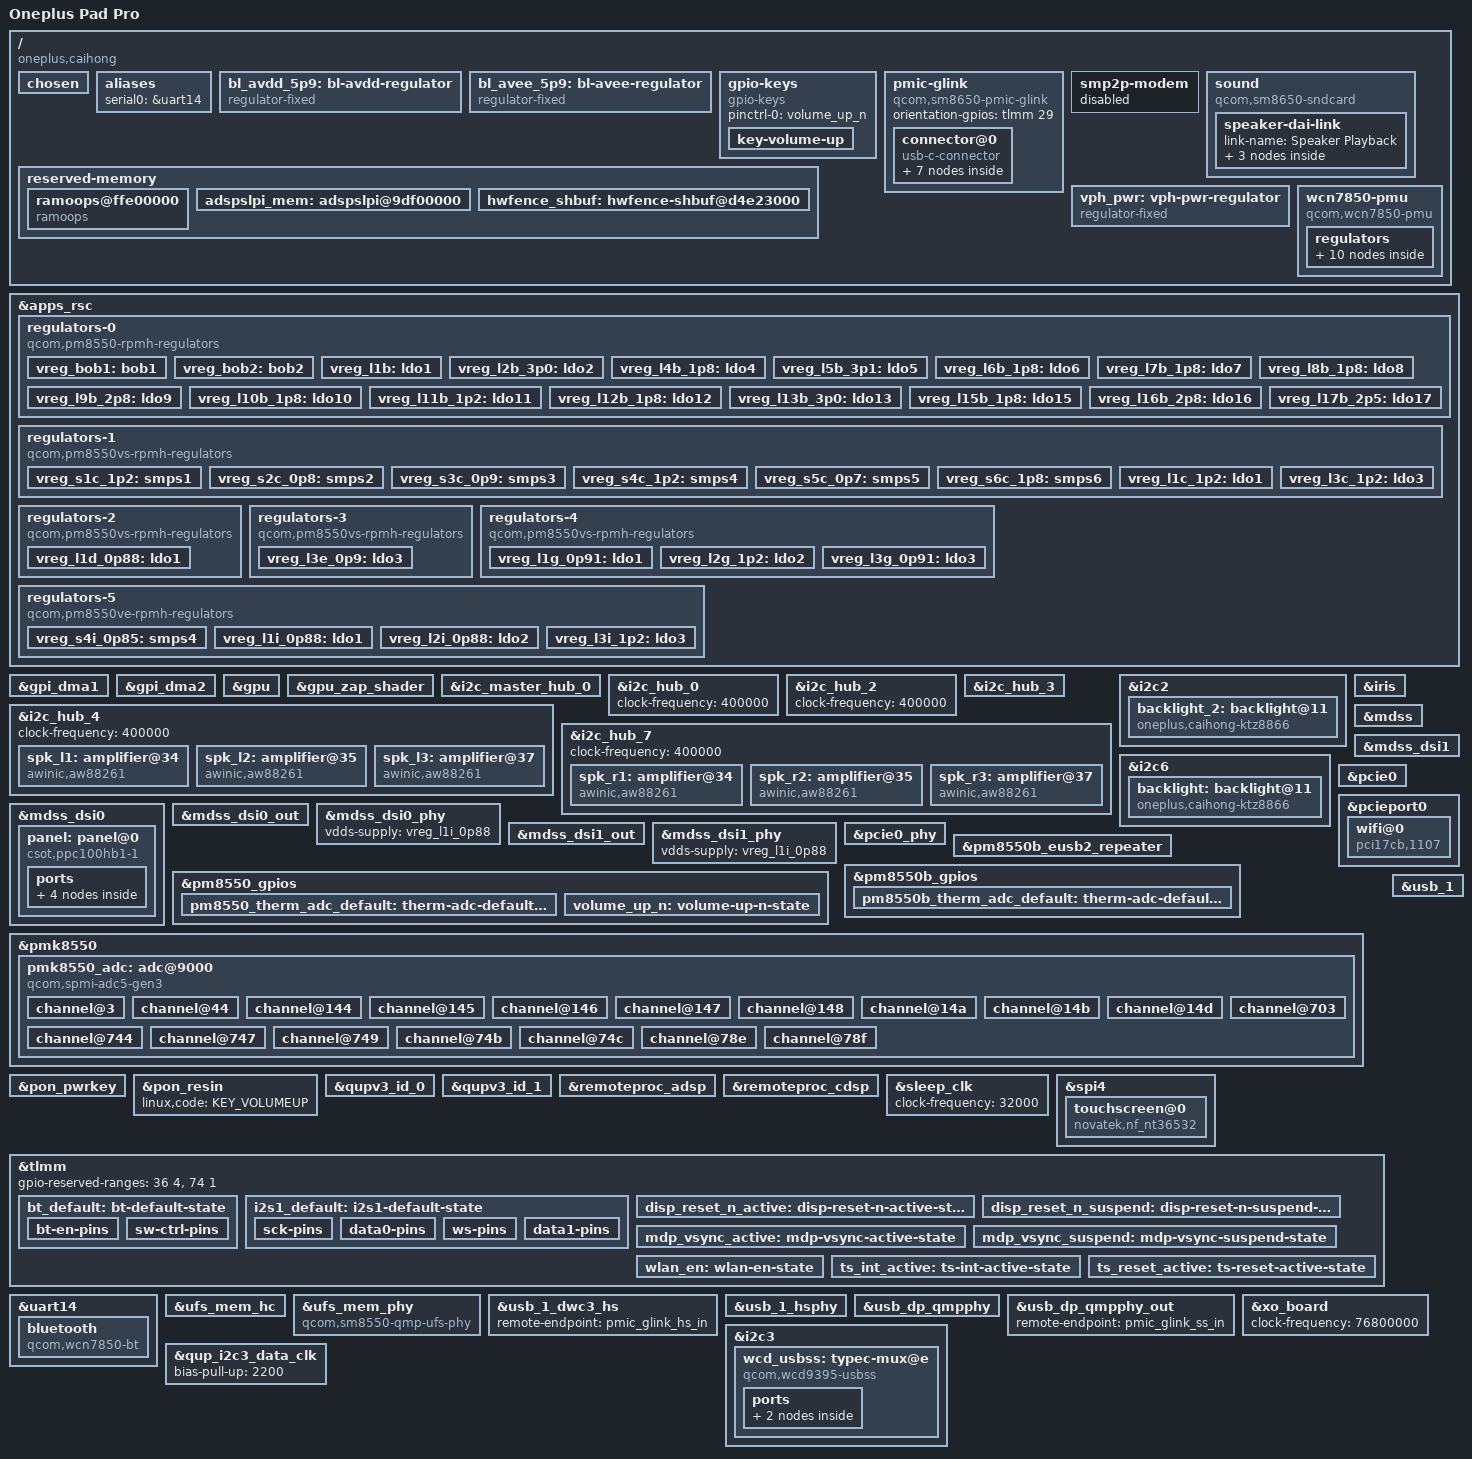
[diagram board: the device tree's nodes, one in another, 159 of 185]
// SPDX-License-Identifier: BSD-3-Clause
/*
 * Based on Qualcomm Reference Device DeviceTree
 *
 * Copyright (c) 2023, Linaro Limited
 * Copyright (c) 2025, Pengyu Luo <mitltlatltl@gmail.com>
 */

/dts-v1/;
#include <dt-bindings/regulator/qcom,rpmh-regulator.h>
#include "sm8650.dtsi"
#include "pm8550.dtsi"
#include "pm8550b.dtsi"
#define PMK8550VE_SID 8
#include "pm8550ve.dtsi"
#include "pm8550vs.dtsi"
#include "pmk8550.dtsi"

/delete-node/ &hwfence_shbuf;

/* No Modem */
/delete-node/ &mpss_mem;
/delete-node/ &q6_mpss_dtb_mem;
/delete-node/ &mpss_dsm_mem;
/delete-node/ &mpss_dsm_mem_2;
/delete-node/ &qlink_logging_mem;
/delete-node/ &remoteproc_mpss;

/* Unused now, and reusable, taking 144 MiB back */
/delete-node/ &trust_ui_vm_mem;
/delete-node/ &oem_vm_mem;
/delete-node/ &qdss_mem;

/ {
	model = "Oneplus Pad Pro";
	compatible = "oneplus,caihong", "qcom,sm8650";
	chassis-type = "tablet";
	chosen {
		#address-cells = <0x02>;
		#size-cells = <0x02>;
		ranges;
		//std-out = "/framebuffer0";
	};
	aliases {
		serial0 = &uart14;
	};

	bl_avdd_5p9: bl-avdd-regulator {
		compatible = "regulator-fixed";
		regulator-name = "bl_avdd_5p9";
		regulator-min-microvolt = <5500000>;
		regulator-max-microvolt = <5500000>;
		regulator-enable-ramp-delay = <233>;
		gpio = <&tlmm 90 GPIO_ACTIVE_HIGH>;
		enable-active-high;
		regulator-boot-on;
	};

	bl_avee_5p9: bl-avee-regulator {
		compatible = "regulator-fixed";
		regulator-name = "bl_avee_5p9";
		regulator-min-microvolt = <5500000>;
		regulator-max-microvolt = <5500000>;
		regulator-enable-ramp-delay = <233>;
		gpio = <&tlmm 91 GPIO_ACTIVE_HIGH>;
		enable-active-high;
		regulator-boot-on;
	};

	gpio-keys {
		compatible = "gpio-keys";

		pinctrl-0 = <&volume_up_n>;
		pinctrl-names = "default";

		key-volume-up {
			label = "Volume Up";
			linux,code = <KEY_VOLUMEDOWN>;
			gpios = <&pm8550_gpios 6 GPIO_ACTIVE_LOW>;
			debounce-interval = <15>;
			linux,can-disable;
			wakeup-source;
		};
	};

	pmic-glink {
		compatible = "qcom,sm8650-pmic-glink",
			     "qcom,sm8550-pmic-glink",
			     "qcom,pmic-glink";
		#address-cells = <1>;
		#size-cells = <0>;
		orientation-gpios = <&tlmm 29 GPIO_ACTIVE_HIGH>;

		connector@0 {
			compatible = "usb-c-connector";
			reg = <0>;

			power-role = "dual";
			data-role = "dual";

			ports {
				#address-cells = <1>;
				#size-cells = <0>;

				port@0 {
					reg = <0>;

					pmic_glink_hs_in: endpoint {
						remote-endpoint = <&usb_1_dwc3_hs>;
					};
				};

				port@1 {
					reg = <1>;

					pmic_glink_ss_in: endpoint {
						remote-endpoint = <&usb_dp_qmpphy_out>;
					};
				};

				port@2 {
					reg = <2>;

					pmic_glink_sbu: endpoint {
						remote-endpoint = <&wcd_usbss_sbu_mux>;
					};
				};

			};
		};
	};

	reserved-memory {
		/*
		 * Keeps the kernel log across a crash or watchdog reset, which
		 * otherwise leaves no trace (no serial console on this tablet).
		 */
		ramoops@ffe00000 {
			compatible = "ramoops";
			reg = <0x0 0xffe00000 0x0 0x200000>;
			record-size = <0x40000>;
			console-size = <0x100000>;
			pmsg-size = <0x40000>;
		};

		adspslpi_mem: adspslpi@9df00000 {
			reg = <0 0x9df00000 0 0x5280000>;
			no-map;
		};

		hwfence_shbuf: hwfence-shbuf@d4e23000 {
			reg = <0 0xd4e23000 0 0x2dd000>;
			no-map;
		};

	};

	/* No Modem */
	smp2p-modem {
		status = "disabled";
	};

	sound {
		compatible = "qcom,sm8650-sndcard", "qcom,sm8450-sndcard";
		model = "OnePlus-Pad2";

		/*
		 * The six AW88261 amplifiers sit on one I2S bus. Mainline
		 * AudioReach has no TDM backend, so they are driven as plain
		 * stereo over SEC_MI2S SD1, each amp picking its side.
		 */
		clocks = <&q6prmcc LPASS_CLK_ID_SEC_MI2S_IBIT LPASS_CLK_ATTRIBUTE_COUPLE_NO>;
		clock-names = "sec-mi2s";

		pinctrl-0 = <&i2s1_default>;
		pinctrl-names = "default";

		speaker-dai-link {
			link-name = "Speaker Playback";

			codec {
				sound-dai = <&spk_l1>, <&spk_l2>, <&spk_l3>,
					    <&spk_r1>, <&spk_r2>, <&spk_r3>;
			};

			cpu {
				sound-dai = <&q6apmbedai SECONDARY_MI2S_RX>;
			};

			platform {
				sound-dai = <&q6apm>;
			};
		};
	};

	vph_pwr: vph-pwr-regulator {
		compatible = "regulator-fixed";

		regulator-name = "vph_pwr";
		regulator-min-microvolt = <3700000>;
		regulator-max-microvolt = <3700000>;

		regulator-always-on;
		regulator-boot-on;
	};

	wcn7850-pmu {
		compatible = "qcom,wcn7850-pmu";

		pinctrl-names = "default";
		pinctrl-0 = <&wlan_en>, <&bt_default>;

		wlan-enable-gpios = <&tlmm 16 GPIO_ACTIVE_HIGH>;
		bt-enable-gpios = <&tlmm 17 GPIO_ACTIVE_HIGH>;

		vdd-supply = <&vreg_s4i_0p85>;
		vddio-supply = <&vreg_l15b_1p8>;
		vddio1p2-supply = <&vreg_l3c_1p2>;
		vddaon-supply = <&vreg_s2c_0p8>;
		vdddig-supply = <&vreg_s3c_0p9>;
		vddrfa1p2-supply = <&vreg_s1c_1p2>;
		vddrfa1p8-supply = <&vreg_s6c_1p8>;

		clocks = <&rpmhcc RPMH_RF_CLK1>;

		regulators {
			vreg_pmu_rfa_cmn: ldo0 {
				regulator-name = "vreg_pmu_rfa_cmn";
			};

			vreg_pmu_aon_0p59: ldo1 {
				regulator-name = "vreg_pmu_aon_0p59";
			};

			vreg_pmu_wlcx_0p8: ldo2 {
				regulator-name = "vreg_pmu_wlcx_0p8";
			};

			vreg_pmu_wlmx_0p85: ldo3 {
				regulator-name = "vreg_pmu_wlmx_0p85";
			};

			vreg_pmu_btcmx_0p85: ldo4 {
				regulator-name = "vreg_pmu_btcmx_0p85";
			};

			vreg_pmu_rfa_0p8: ldo5 {
				regulator-name = "vreg_pmu_rfa_0p8";
			};

			vreg_pmu_rfa_1p2: ldo6 {
				regulator-name = "vreg_pmu_rfa_1p2";
			};

			vreg_pmu_rfa_1p8: ldo7 {
				regulator-name = "vreg_pmu_rfa_1p8";
			};

			vreg_pmu_pcie_0p9: ldo8 {
				regulator-name = "vreg_pmu_pcie_0p9";
			};

			vreg_pmu_pcie_1p8: ldo9 {
				regulator-name = "vreg_pmu_pcie_1p8";
			};
		};
	};
};

&apps_rsc {
	regulators-0 {
		compatible = "qcom,pm8550-rpmh-regulators";

		vdd-bob1-supply = <&vph_pwr>;
		vdd-bob2-supply = <&vph_pwr>;
		vdd-l2-l13-l14-supply = <&vreg_bob1>;
		vdd-l3-supply = <&vreg_s1c_1p2>;
		vdd-l5-l16-supply = <&vreg_bob1>;
		vdd-l6-l7-supply = <&vreg_bob1>;
		vdd-l8-l9-supply = <&vreg_bob1>;
		vdd-l11-supply = <&vreg_s1c_1p2>;
		vdd-l12-supply = <&vreg_s6c_1p8>;
		vdd-l15-supply = <&vreg_s6c_1p8>;
		vdd-l17-supply = <&vreg_bob2>;

		qcom,pmic-id = "b";

		vreg_bob1: bob1 {
			regulator-name = "vreg_bob1";
			regulator-min-microvolt = <3008000>;
			regulator-max-microvolt = <3960000>;
			regulator-initial-mode = <RPMH_REGULATOR_MODE_HPM>;
			regulator-always-on;
		};

		vreg_bob2: bob2 {
			regulator-name = "vreg_bob2";
			regulator-min-microvolt = <2704000>;
			regulator-max-microvolt = <3008000>;
			regulator-initial-mode = <RPMH_REGULATOR_MODE_HPM>;
			regulator-always-on;
		};

		vreg_l1b: ldo1 {
			regulator-name = "vreg_l1b";
			regulator-min-microvolt = <1800000>;
			regulator-max-microvolt = <1800000>;
			regulator-initial-mode = <RPMH_REGULATOR_MODE_HPM>;
			regulator-allow-set-load;
			regulator-allowed-modes = <RPMH_REGULATOR_MODE_LPM
						   RPMH_REGULATOR_MODE_HPM>;
			regulator-always-on;
		};

		vreg_l2b_3p0: ldo2 {
			regulator-name = "vreg_l2b_3p0";
			regulator-min-microvolt = <3008000>;
			regulator-max-microvolt = <3008000>;
			regulator-initial-mode = <RPMH_REGULATOR_MODE_HPM>;
			regulator-allow-set-load;
			regulator-allowed-modes = <RPMH_REGULATOR_MODE_LPM
						   RPMH_REGULATOR_MODE_HPM>;
		};

		vreg_l4b_1p8: ldo4 {
			regulator-name = "vreg_l4b_1p8";
			regulator-min-microvolt = <1800000>;
			regulator-max-microvolt = <1800000>;
			regulator-initial-mode = <RPMH_REGULATOR_MODE_HPM>;
			regulator-allow-set-load;
			regulator-allowed-modes = <RPMH_REGULATOR_MODE_LPM
						   RPMH_REGULATOR_MODE_HPM>;
		};

		vreg_l5b_3p1: ldo5 {
			regulator-name = "vreg_l5b_3p1";
			regulator-min-microvolt = <3104000>;
			regulator-max-microvolt = <3104000>;
			regulator-initial-mode = <RPMH_REGULATOR_MODE_HPM>;
			regulator-allow-set-load;
			regulator-allowed-modes = <RPMH_REGULATOR_MODE_LPM
						   RPMH_REGULATOR_MODE_HPM>;
		};
		vreg_l6b_1p8: ldo6 {
			regulator-name = "vreg_l6b_1p8";
			regulator-min-microvolt = <1800000>;
			regulator-max-microvolt = <3008000>;
			regulator-initial-mode = <RPMH_REGULATOR_MODE_HPM>;
			regulator-allow-set-load;
			regulator-allowed-modes = <RPMH_REGULATOR_MODE_LPM
						   RPMH_REGULATOR_MODE_HPM>;
			regulator-always-on;
		};
		vreg_l7b_1p8: ldo7 {
			regulator-name = "vreg_l7b_1p8";
			regulator-min-microvolt = <1800000>;
			regulator-max-microvolt = <3008000>;
			regulator-initial-mode = <RPMH_REGULATOR_MODE_HPM>;
			regulator-always-on;
		};

		vreg_l8b_1p8: ldo8 {
			regulator-name = "vreg_l8b_1p8";
			regulator-min-microvolt = <1800000>;
			regulator-max-microvolt = <3008000>;
			regulator-initial-mode = <RPMH_REGULATOR_MODE_HPM>;
			regulator-allow-set-load;
			regulatorepss_l3-allowed-modes = <RPMH_REGULATOR_MODE_LPM
						   RPMH_REGULATOR_MODE_HPM>;
			regulator-always-on;
		};
		vreg_l9b_2p8: ldo9 {
			regulator-name = "vreg_l9b_2p8";
			regulator-min-microvolt = <2800000>;
			regulator-max-microvolt = <2800000>;
			regulator-initial-mode = <RPMH_REGULATOR_MODE_HPM>;
			regulator-allow-set-load;
			regulator-allowed-modes = <RPMH_REGULATOR_MODE_LPM
						   RPMH_REGULATOR_MODE_HPM>;
		};

		vreg_l10b_1p8: ldo10 {
			regulator-name = "vreg_l10b_1p8";
			regulator-min-microvolt = <1800000>;
			regulator-max-microvolt = <1800000>;
			regulator-initial-mode = <RPMH_REGULATOR_MODE_HPM>;
			regulator-allow-set-load;
			regulator-allowed-modes = <RPMH_REGULATOR_MODE_LPM
						   RPMH_REGULATOR_MODE_HPM>;
		};
		vreg_l11b_1p2: ldo11 {
			regulator-name = "vreg_l11b_1p2";
			regulator-min-microvolt = <1200000>;
			regulator-max-microvolt = <1200000>;
			regulator-initial-mode = <RPMH_REGULATOR_MODE_HPM>;
			regulator-allow-set-load;
			regulator-allowed-modes = <RPMH_REGULATOR_MODE_LPM
						   RPMH_REGULATOR_MODE_HPM>;
			regulator-always-on;
		};
		vreg_l12b_1p8: ldo12 {
			regulator-name = "vreg_l12b_1p8";
			regulator-min-microvolt = <1800000>;
			regulator-max-microvolt = <1800000>;
			regulator-initial-mode = <RPMH_REGULATOR_MODE_HPM>;
			regulator-allow-set-load;
			regulator-always-on;
			regulator-allowed-modes = <RPMH_REGULATOR_MODE_LPM
						   RPMH_REGULATOR_MODE_HPM>;
		};
		vreg_l13b_3p0: ldo13 {
			regulator-name = "vreg_l13b_3p0";
			regulator-min-microvolt = <3000000>;
			regulator-max-microvolt = <3200000>;
			regulator-initial-mode = <RPMH_REGULATOR_MODE_HPM>;
			regulator-allow-set-load;
			regulator-allowed-modes = <RPMH_REGULATOR_MODE_LPM
						   RPMH_REGULATOR_MODE_HPM>;
			regulator-always-on;
		};
		vreg_l15b_1p8: ldo15 {
			regulator-name = "vreg_l15b_1p8";
			regulator-min-microvolt = <1800000>;
			regulator-max-microvolt = <1800000>;
			regulator-initial-mode = <RPMH_REGULATOR_MODE_HPM>;
			regulator-allow-set-load;
			regulator-allowed-modes = <RPMH_REGULATOR_MODE_LPM
						   RPMH_REGULATOR_MODE_HPM>;
		};

		vreg_l16b_2p8: ldo16 {
			regulator-name = "vreg_l16b_2p8";
			regulator-min-microvolt = <2800000>;
			regulator-max-microvolt = <2800000>;
			regulator-initial-mode = <RPMH_REGULATOR_MODE_HPM>;
			regulator-allow-set-load;
			regulator-allowed-modes = <RPMH_REGULATOR_MODE_LPM
						   RPMH_REGULATOR_MODE_HPM>;
		};

		vreg_l17b_2p5: ldo17 {
			regulator-name = "vreg_l17b_2p5";
			regulator-min-microvolt = <2504000>;
			regulator-max-microvolt = <2504000>;
			regulator-initial-mode = <RPMH_REGULATOR_MODE_HPM>;
			regulator-allow-set-load;
			regulator-allowed-modes = <RPMH_REGULATOR_MODE_LPM
						   RPMH_REGULATOR_MODE_HPM>;
		};
	};

	regulators-1 {
		compatible = "qcom,pm8550vs-rpmh-regulators";

		vdd-l1-supply = <&vreg_s1c_1p2>;
		vdd-l2-supply = <&vreg_s1c_1p2>;
		vdd-l3-supply = <&vreg_s1c_1p2>;
		vdd-s1-supply = <&vph_pwr>;
		vdd-s2-supply = <&vph_pwr>;
		vdd-s3-supply = <&vph_pwr>;
		vdd-s4-supply = <&vph_pwr>;
		vdd-s5-supply = <&vph_pwr>;
		vdd-s6-supply = <&vph_pwr>;

		qcom,pmic-id = "c";

		vreg_s1c_1p2: smps1 {
			regulator-name = "vreg_s1c_1p2";
			regulator-min-microvolt = <1316000>;
			regulator-max-microvolt = <1316000>;
			regulator-initial-mode = <RPMH_REGULATOR_MODE_HPM>;
		};

		vreg_s2c_0p8: smps2 {
			regulator-name = "vreg_s2c_0p8";
			regulator-min-microvolt = <976000>;
			regulator-max-microvolt = <976000>;
			regulator-initial-mode = <RPMH_REGULATOR_MODE_HPM>;
		};

		vreg_s3c_0p9: smps3 {
			regulator-name = "vreg_s3c_0p9";
			regulator-min-microvolt = <916000>;
			regulator-max-microvolt = <916000>;
			regulator-initial-mode = <RPMH_REGULATOR_MODE_HPM>;
		};

		vreg_s4c_1p2: smps4 {
			regulator-name = "vreg_s4c_1p2";
			regulator-min-microvolt = <1200000>;
			regulator-max-microvolt = <1280000>;
			regulator-initial-mode = <RPMH_REGULATOR_MODE_HPM>;
		};

		vreg_s5c_0p7: smps5 {
			regulator-name = "vreg_s5c_0p7";
			regulator-min-microvolt = <300000>;
			regulator-max-microvolt = <900000>;
			regulator-initial-mode = <RPMH_REGULATOR_MODE_HPM>;
		};

		vreg_s6c_1p8: smps6 {
			regulator-name = "vreg_s6c_1p8";
			regulator-min-microvolt = <1864000>;
			regulator-max-microvolt = <1864000>;
			regulator-initial-mode = <RPMH_REGULATOR_MODE_HPM>;
		};

		vreg_l1c_1p2: ldo1 {
			regulator-name = "vreg_l1c_1p2";
			regulator-min-microvolt = <1100000>;
			regulator-max-microvolt = <1200000>;
			regulator-initial-mode = <RPMH_REGULATOR_MODE_HPM>;
			regulator-allow-set-load;
			regulator-allowed-modes = <RPMH_REGULATOR_MODE_LPM
						   RPMH_REGULATOR_MODE_HPM>;
		};

		vreg_l3c_1p2: ldo3 {
			regulator-name = "vreg_l3c_1p2";
			regulator-min-microvolt = <1200000>;
			regulator-max-microvolt = <1200000>;
			regulator-initial-mode = <RPMH_REGULATOR_MODE_HPM>;
			regulator-allow-set-load;
			regulator-allowed-modes = <RPMH_REGULATOR_MODE_LPM
						   RPMH_REGULATOR_MODE_HPM>;
		};
	};

	regulators-2 {
		compatible = "qcom,pm8550vs-rpmh-regulators";

		vdd-l1-supply = <&vreg_s3c_0p9>;

		qcom,pmic-id = "d";

		vreg_l1d_0p88: ldo1 {
			regulator-name = "vreg_l1d_0p88";
			regulator-min-microvolt = <880000>;
			regulator-max-microvolt = <920000>;
			regulator-initial-mode = <RPMH_REGULATOR_MODE_HPM>;
			regulator-allow-set-load;
			regulator-allowed-modes = <RPMH_REGULATOR_MODE_LPM
						   RPMH_REGULATOR_MODE_HPM>;
		};
	};

	regulators-3 {
		compatible = "qcom,pm8550vs-rpmh-regulators";

		vdd-l3-supply = <&vreg_s3c_0p9>;

		qcom,pmic-id = "e";

		vreg_l3e_0p9: ldo3 {
			regulator-name = "vreg_l3e_0p9";
			regulator-min-microvolt = <880000>;
			regulator-max-microvolt = <920000>;
			regulator-initial-mode = <RPMH_REGULATOR_MODE_HPM>;
			regulator-allow-set-load;
			regulator-allowed-modes = <RPMH_REGULATOR_MODE_LPM
						   RPMH_REGULATOR_MODE_HPM>;
		};
	};

	regulators-4 {
		compatible = "qcom,pm8550vs-rpmh-regulators";

		vdd-l1-supply = <&vreg_s3c_0p9>;
		vdd-l3-supply = <&vreg_s3c_0p9>;

		qcom,pmic-id = "g";

		vreg_l1g_0p91: ldo1 {
			regulator-name = "vreg_l1g_0p91";
			regulator-min-microvolt = <912000>;
			regulator-max-microvolt = <920000>;
			regulator-initial-mode = <RPMH_REGULATOR_MODE_HPM>;
			regulator-allow-set-load;
			regulator-allowed-modes = <RPMH_REGULATOR_MODE_LPM
						   RPMH_REGULATOR_MODE_HPM>;
		};

		vreg_l2g_1p2: ldo2 {
			regulator-name = "vreg_l2g_1p2";
			regulator-min-microvolt = <1200000>;
			regulator-max-microvolt = <1200000>;
			regulator-initial-mode = <RPMH_REGULATOR_MODE_HPM>;
			regulator-allow-set-load;
			regulator-allowed-modes = <RPMH_REGULATOR_MODE_LPM
						   RPMH_REGULATOR_MODE_HPM>;
		};

		vreg_l3g_0p91: ldo3 {
			regulator-name = "vreg_l3g_0p91";
			regulator-min-microvolt = <880000>;
			regulator-max-microvolt = <912000>;
			regulator-initial-mode = <RPMH_REGULATOR_MODE_HPM>;
			regulator-allow-set-load;
			regulator-allowed-modes = <RPMH_REGULATOR_MODE_LPM
						   RPMH_REGULATOR_MODE_HPM>;
		};
	};

	regulators-5 {
		compatible = "qcom,pm8550ve-rpmh-regulators";

		vdd-l1-supply = <&vreg_s3c_0p9>;
		vdd-l2-supply = <&vreg_s3c_0p9>;
		vdd-l3-supply = <&vreg_s1c_1p2>;
		vdd-s4-supply = <&vph_pwr>;

		qcom,pmic-id = "i";

		vreg_s4i_0p85: smps4 {
			regulator-name = "vreg_s4i_0p85";
			regulator-min-microvolt = <940000>;
			regulator-max-microvolt = <940000>;
			regulator-initial-mode = <RPMH_REGULATOR_MODE_HPM>;
		};

		vreg_l1i_0p88: ldo1 {
			regulator-name = "vreg_l1i_0p88";
			regulator-min-microvolt = <880000>;
			regulator-max-microvolt = <912000>;
			regulator-initial-mode = <RPMH_REGULATOR_MODE_HPM>;
			regulator-allow-set-load;
			regulator-allowed-modes = <RPMH_REGULATOR_MODE_LPM
						   RPMH_REGULATOR_MODE_HPM>;
		};

		vreg_l2i_0p88: ldo2 {
			regulator-name = "vreg_l2i_0p88";
			regulator-min-microvolt = <880000>;
			regulator-max-microvolt = <912000>;
			regulator-initial-mode = <RPMH_REGULATOR_MODE_HPM>;
			regulator-allow-set-load;
			regulator-allowed-modes = <RPMH_REGULATOR_MODE_LPM
						   RPMH_REGULATOR_MODE_HPM>;
		};

		vreg_l3i_1p2: ldo3 {
			regulator-name = "vreg_l3i_0p91";
			regulator-min-microvolt = <1200000>;
			regulator-max-microvolt = <1200000>;
			regulator-initial-mode = <RPMH_REGULATOR_MODE_HPM>;
			regulator-allow-set-load;
			regulator-allowed-modes = <RPMH_REGULATOR_MODE_LPM
						   RPMH_REGULATOR_MODE_HPM>;
		};
	};
};

&gpi_dma1 {
	status = "okay";
};

&gpi_dma2 {
	status = "okay";
};

&gpu {
	status = "okay";
};

&gpu_zap_shader {
	firmware-name = "qcom/sm8650/Oneplus/caihong/gen70900_zap.mbn";
};

&i2c_master_hub_0 {
	status = "okay";
};

&i2c_hub_0 {
	clock-frequency = <400000>;

	status = "okay";

	/* sc8547-charger-secondary@6F */
};

&i2c_hub_2 {
	clock-frequency = <400000>;

	status = "okay";

	/* sc8547-charger-primary@6F */
};

&i2c_hub_3 {
	status = "okay";

	/* pencil-wireless-charger-cps8601@41 */
};

&i2c_hub_4 {
	clock-frequency = <400000>;

	status = "okay";

	/* left speakers */
	spk_l1: amplifier@34 {
		compatible = "awinic,aw88261";
		reg = <0x34>;
		#sound-dai-cells = <0>;
		dvdd-supply = <&vreg_l15b_1p8>;
		firmware-name = "aw882xx_acf.bin";
		awinic,audio-channel = <0>;
		awinic,i2s-chsel = <1>;
		awinic,sync-flag;
		sound-name-prefix = "SpkL1";
	};

	spk_l2: amplifier@35 {
		compatible = "awinic,aw88261";
		reg = <0x35>;
		#sound-dai-cells = <0>;
		dvdd-supply = <&vreg_l15b_1p8>;
		firmware-name = "aw882xx_acf.bin";
		awinic,audio-channel = <2>;
		awinic,i2s-chsel = <1>;
		awinic,sync-flag;
		sound-name-prefix = "SpkL2";
	};

	spk_l3: amplifier@37 {
		compatible = "awinic,aw88261";
		reg = <0x37>;
		#sound-dai-cells = <0>;
		dvdd-supply = <&vreg_l15b_1p8>;
		firmware-name = "aw882xx_acf.bin";
		awinic,audio-channel = <6>;
		awinic,i2s-chsel = <1>;
		awinic,sync-flag;
		sound-name-prefix = "SpkL3";
	};
};

&i2c_hub_7 {
	clock-frequency = <400000>;

	status = "okay";

	/* right speakers */
	spk_r1: amplifier@34 {
		compatible = "awinic,aw88261";
		reg = <0x34>;
		#sound-dai-cells = <0>;
		dvdd-supply = <&vreg_l15b_1p8>;
		firmware-name = "aw882xx_acf.bin";
		awinic,audio-channel = <1>;
		awinic,i2s-chsel = <2>;
		awinic,sync-flag;
		sound-name-prefix = "SpkR1";
	};

	spk_r2: amplifier@35 {
		compatible = "awinic,aw88261";
		reg = <0x35>;
		#sound-dai-cells = <0>;
		dvdd-supply = <&vreg_l15b_1p8>;
		firmware-name = "aw882xx_acf.bin";
		awinic,audio-channel = <3>;
		awinic,i2s-chsel = <2>;
		awinic,sync-flag;
		sound-name-prefix = "SpkR2";
	};

	spk_r3: amplifier@37 {
		compatible = "awinic,aw88261";
		reg = <0x37>;
		#sound-dai-cells = <0>;
		dvdd-supply = <&vreg_l15b_1p8>;
		firmware-name = "aw882xx_acf.bin";
		awinic,audio-channel = <5>;
		awinic,i2s-chsel = <2>;
		awinic,sync-flag;
		sound-name-prefix = "SpkR3";
	};
};

&i2c2 {
	status = "okay";

	/* secondary kinetic,ktz8866@11 */

	backlight_2: backlight@11 {
		compatible = "oneplus,caihong-ktz8866", "kinetic,ktz8866";
		reg = <0x11>;
		/* HW enable shared with the primary KTZ8866 */
		enable-gpios = <&tlmm 89 GPIO_ACTIVE_HIGH>;
		vddpos-supply = <&bl_avdd_5p9>;
		vddneg-supply = <&bl_avee_5p9>;
		current-num-sinks = <5>;
		kinetic,current-ramp-delay-ms = <128>;
		kinetic,led-enable-ramp-delay-ms = <1>;
		kinetic,enable-lcd-bias;
		default-brightness = <100>;
	};

};

&i2c6 {
	status = "okay";

	backlight: backlight@11 {
		compatible = "oneplus,caihong-ktz8866", "kinetic,ktz8866";
		reg = <0x11>;
		enable-gpios = <&tlmm 89 GPIO_ACTIVE_HIGH>;
		vddpos-supply = <&bl_avdd_5p9>;
		vddneg-supply = <&bl_avee_5p9>;
		current-num-sinks = <5>;
		kinetic,current-ramp-delay-ms = <128>;
		kinetic,led-enable-ramp-delay-ms = <1>;
		kinetic,enable-lcd-bias;
		default-brightness = <100>;
	};

};

&iris {
	firmware-name = "qcom/sm8650/Oneplus/caihong/vpu33_4v.mbn";

	status = "okay";
};

&mdss {
	status = "okay";
};

&mdss_dsi0 {
	vdda-supply = <&vreg_l3i_1p2>;

	qcom,dual-dsi-mode;
	qcom,dual-panel;
	qcom,master-dsi;
	qcom,sync-dual-dsi;

	status = "okay";

	panel: panel@0 {
		status = "okay";
		compatible = "csot,ppc100hb1-1","novatek,nt36532";
		reg = <0>;

		reset-gpios = <&tlmm 133 GPIO_ACTIVE_LOW>;

		vddio-supply = <&vreg_l12b_1p8>;
		vci-supply = <&vreg_l13b_3p0>;
		vdd-supply = <&vreg_l11b_1p2>;
		backlight = <&backlight>;
		pinctrl-0 = <&disp_reset_n_active>, <&mdp_vsync_active>;
		pinctrl-1 = <&disp_reset_n_suspend>, <&mdp_vsync_suspend>;
		pinctrl-names = "default", "sleep";

		ports {
			#address-cells = <1>;
			#size-cells = <0>;

			port@0 {
				reg = <0>;

				panel_in_0: endpoint {
					remote-endpoint = <&mdss_dsi0_out>;
				};
			};

			port@1 {
				reg = <1>;

				panel_in_1: endpoint {
					remote-endpoint = <&mdss_dsi1_out>;
				};
			};
		};
	};
};

&mdss_dsi0_out {
	status = "okay";
	remote-endpoint = <&panel_in_0>;
	data-lanes = <0 1 2 3>;
};

&mdss_dsi0_phy {
	vdds-supply = <&vreg_l1i_0p88>;
	status = "okay";
};

&mdss_dsi1 {
	vdda-supply = <&vreg_l3i_1p2>;

	qcom,dual-dsi-mode;
	qcom,dual-panel;
	qcom,sync-dual-dsi;
	qcom,slave-dsi;
	status = "okay";

	assigned-clock-parents = <&mdss_dsi0_phy DSI_BYTE_PLL_CLK>,
				 <&mdss_dsi0_phy DSI_PIXEL_PLL_CLK>;
};

&mdss_dsi1_out {
	status = "okay";
	remote-endpoint = <&panel_in_1>;
	data-lanes = <0 1 2 3>;
};

&mdss_dsi1_phy {
	vdds-supply = <&vreg_l1i_0p88>;
	status = "okay";
};

/*
 * DisplayPort over USB-C kept disabled for now; not needed for the DSI
 * panel.
&mdss_dp0 {
	status = "okay";
};

&mdss_dp0_out {
	status = "okay";
	data-lanes = <0 1>;
};
*/

&pcie0 {
	/*
	 * MSIs written by the endpoint never reach the GIC ITS on this board
	 * (the root port's own MSIs do), so use the controller's internal
	 * MSI instead.
	 */
	/delete-property/ msi-map;
	/delete-property/ msi-map-mask;

	wake-gpios = <&tlmm 96 GPIO_ACTIVE_HIGH>;
	perst-gpios = <&tlmm 94 GPIO_ACTIVE_LOW>;

	pinctrl-0 = <&pcie0_default_state>;
	pinctrl-names = "default";

	status = "okay";
};

&pcieport0 {
	wifi@0 {
		compatible = "pci17cb,1107";
		reg = <0x10000 0x0 0x0 0x0 0x0>;

		vddrfacmn-supply = <&vreg_pmu_rfa_cmn>;
		vddaon-supply = <&vreg_pmu_aon_0p59>;
		vddwlcx-supply = <&vreg_pmu_wlcx_0p8>;
		vddwlmx-supply = <&vreg_pmu_wlmx_0p85>;
		vddrfa0p8-supply = <&vreg_pmu_rfa_0p8>;
		vddrfa1p2-supply = <&vreg_pmu_rfa_1p2>;
		vddrfa1p8-supply = <&vreg_pmu_rfa_1p8>;
		vddpcie0p9-supply = <&vreg_pmu_pcie_0p9>;
		vddpcie1p8-supply = <&vreg_pmu_pcie_1p8>;
	};
};

&pcie0_phy {
	vdda-phy-supply = <&vreg_l1i_0p88>;
	vdda-pll-supply = <&vreg_l3i_1p2>;

	status = "okay";
};

&pm8550_gpios {
	/* Thermistors read through the ADC: battery connector, SuperVOOC MOS */
	pm8550_therm_adc_default: therm-adc-default-state {
		pins = "gpio4", "gpio12";
		function = "normal";
		bias-high-impedance;
		bias-disable;
	};

	volume_up_n: volume-up-n-state {
		pins = "gpio6";
		function = "normal";
		bias-pull-up;
		input-enable;
		power-source = <1>;
	};
};

&pm8550b_eusb2_repeater {
	vdd18-supply = <&vreg_l15b_1p8>;
	vdd3-supply = <&vreg_l5b_3p1>;
};

&pm8550b_gpios {
	/*
	 * Thermistors read through the ADC: USB port left/right and sub-board.
	 * Left in their reset state (input, 10 uA pull-down) they read ~60 C.
	 */
	pm8550b_therm_adc_default: therm-adc-default-state {
		pins = "gpio5", "gpio6", "gpio10";
		function = "normal";
		bias-high-impedance;
		bias-disable;
	};
};

&pmk8550 {
	pmk8550_adc: adc@9000 {
		compatible = "qcom,spmi-adc5-gen3";
		reg = <0x9000>, <0x9100>;
		interrupts = <0x0 0x90 0x1 IRQ_TYPE_EDGE_RISING>,
			     <0x0 0x91 0x1 IRQ_TYPE_EDGE_RISING>;
		#address-cells = <1>;
		#size-cells = <0>;
		#io-channel-cells = <1>;
		#thermal-sensor-cells = <1>;

		pinctrl-0 = <&pm8550_therm_adc_default>, <&pm8550b_therm_adc_default>;
		pinctrl-names = "default";

		channel@3 {
			reg = <0x3>;
			label = "pmk8550_die_temp";
			qcom,pre-scaling = <1 1>;
		};

		channel@44 {
			reg = <0x44>;
			label = "pmk8550_xo_therm";
			qcom,pre-scaling = <1 1>;
			qcom,ratiometric;
			qcom,hw-settle-time = <200>;
		};

		channel@144 {
			reg = <0x144>;
			label = "pm8550_msm_therm";
			qcom,pre-scaling = <1 1>;
			qcom,ratiometric;
			qcom,hw-settle-time = <200>;
		};

		channel@145 {
			reg = <0x145>;
			label = "pm8550_cam_flash_therm";
			qcom,pre-scaling = <1 1>;
			qcom,ratiometric;
			qcom,hw-settle-time = <200>;
		};

		channel@146 {
			reg = <0x146>;
			label = "pm8550_wlan_therm";
			qcom,pre-scaling = <1 1>;
			qcom,ratiometric;
			qcom,hw-settle-time = <200>;
		};

		channel@147 {
			reg = <0x147>;
			label = "pm8550_pa_therm_1";
			qcom,pre-scaling = <1 1>;
			qcom,ratiometric;
			qcom,hw-settle-time = <200>;
		};

		channel@148 {
			reg = <0x148>;
			label = "pm8550_rear_tof_therm";
			qcom,pre-scaling = <1 1>;
			qcom,ratiometric;
			qcom,hw-settle-time = <200>;
		};

		channel@14a {
			reg = <0x14a>;
			label = "pm8550_pa_therm_2";
			qcom,pre-scaling = <1 1>;
			qcom,ratiometric;
			qcom,hw-settle-time = <200>;
		};

		channel@14b {
			reg = <0x14b>;
			label = "batt_con_therm";
			qcom,pre-scaling = <1 1>;
			qcom,ratiometric;
			qcom,hw-settle-time = <200>;
		};

		channel@14d {
			reg = <0x14d>;
			label = "svooc_mos_btb_therm";
			qcom,pre-scaling = <1 1>;
			qcom,ratiometric;
			qcom,hw-settle-time = <200>;
		};

		channel@703 {
			reg = <0x703>;
			label = "pm8550b_die_temp";
			qcom,pre-scaling = <1 1>;
		};

		channel@744 {
			reg = <0x744>;
			label = "pm8550b_batt_therm";
			qcom,pre-scaling = <1 1>;
			qcom,ratiometric;
			qcom,hw-settle-time = <200>;
		};

		channel@747 {
			reg = <0x747>;
			label = "usb_con_therm";
			qcom,pre-scaling = <1 1>;
			qcom,ratiometric;
			qcom,hw-settle-time = <200>;
		};

		channel@749 {
			reg = <0x749>;
			label = "usb_temp_r";
			qcom,pre-scaling = <1 1>;
			qcom,ratiometric;
			qcom,hw-settle-time = <200>;
		};

		channel@74b {
			reg = <0x74b>;
			label = "usb_temp_l";
			qcom,pre-scaling = <1 1>;
			qcom,ratiometric;
			qcom,hw-settle-time = <200>;
		};

		channel@74c {
			reg = <0x74c>;
			label = "subboard_therm";
			qcom,pre-scaling = <1 1>;
			qcom,ratiometric;
			qcom,hw-settle-time = <200>;
		};

		channel@78e {
			reg = <0x78e>;
			label = "pm8550b_vph_pwr";
			qcom,pre-scaling = <1 3>;
		};

		channel@78f {
			reg = <0x78f>;
			label = "pm8550b_vbat_sns_qbg";
			qcom,pre-scaling = <1 3>;
		};
	};
};

&pon_pwrkey {
	status = "okay";
};

&pon_resin {
	linux,code = <KEY_VOLUMEUP>;

	status = "okay";
};

&qupv3_id_0 {
	status = "okay";
};

&qupv3_id_1 {
	status = "okay";
};

&remoteproc_adsp {
	firmware-name = "qcom/sm8650/Oneplus/caihong/adsp.mbn",
			"qcom/sm8650/Oneplus/caihong/adsp_dtb.mbn";

	status = "okay";
};

&remoteproc_cdsp {
	firmware-name = "qcom/sm8650/Oneplus/caihong/cdsp.mbn",
			"qcom/sm8650/Oneplus/caihong/cdsp_dtb.mbn";

	status = "okay";
};

&sleep_clk {
	clock-frequency = <32000>;
};

&spi4 {
	status = "okay";

	/*
	 * Novatek NT36532 in-cell touch, driven by the out-of-tree Oplus
	 * "no-flash" driver. It has no flash, so its firmware is downloaded on
	 * every power-up from firmware-data-0, which the board packaging adds
	 * to the DTB (the firmware is not redistributable).
	 */
	touchscreen@0 {
		compatible = "novatek,nf_nt36532";
		reg = <0>;
		spi-max-frequency = <12000000>;

		interrupts-extended = <&tlmm 162 IRQ_TYPE_EDGE_FALLING>;
		irq-gpio = <&tlmm 162 0x2002>;
		reset-gpio = <&tlmm 161 GPIO_ACTIVE_HIGH>;
		cs-gpio = <&tlmm 51 GPIO_ACTIVE_HIGH>;

		pinctrl-0 = <&ts_int_active>, <&ts_reset_active>;
		pinctrl-names = "default";

		panel = <&panel>;

		project_id = <23926>;
		firmware_name = "0X21N2NI9N19";
		platform_support_project = <23926 23927 23976 23978>;
		platform_support_project_dir = <23926 23926 23926 23926>;
		platform_support_project_commandline =
			"mdss_dsi_panel_csot_nt36532_2120_3000_dual_dsc_144hz_vid";

		touchpanel,max-num-support = <10>;
		touchpanel,tx-rx-num = <60 40>;
		touchpanel,panel-coords = <21200 30000>;
		touchpanel,display-coords = <2120 3000>;
		touchpanel,touchmajor-limit = <0 60>;
		touchpanel,irq_need_dev_resume_time = <500>;
		touchpanel,int-mode = <1>;
		touchpanel,button-type = <4>;
		tp_type = <15>;
		panel_type = <15>;

		incell_screen;
		fw_edge_limit_support;
		black_gesture_support;
		charger_pump_support;
		esd_handle_support;
		black_gesture_test_support;
		game_switch_support;
		noflash_support;
		lcd_trigger_load_tp_fw_support;
		smart_gesture_support;
		pressure_report_support;
		pen_support;
		waterproof_support;
		irq_need_dev_resume_ok;
		fw_update_app_support;
		health_monitor_support;
		fw_update_in_probe_with_headfile;
		black_gesture_indep_support;
		report_rate_limit;
	};
};

&tlmm {
	gpio-reserved-ranges = <36 4>, <74 1>;

	bt_default: bt-default-state {
		bt-en-pins {
			pins = "gpio17";
			function = "gpio";
			drive-strength = <16>;
			bias-disable;
		};

		sw-ctrl-pins {
			pins = "gpio18";
			function = "gpio";
			bias-pull-down;
		};
	};
	i2s1_default: i2s1-default-state {
		sck-pins {
			pins = "gpio121";
			function = "i2s1_sck";
			drive-strength = <6>;
			bias-disable;
		};

		data0-pins {
			pins = "gpio122";
			function = "i2s1_data0";
			drive-strength = <6>;
			bias-disable;
		};

		ws-pins {
			pins = "gpio123";
			function = "i2s1_ws";
			drive-strength = <6>;
			bias-disable;
		};

		data1-pins {
			pins = "gpio124";
			function = "i2s1_data1";
			drive-strength = <6>;
			bias-disable;
		};
	};

	disp_reset_n_active: disp-reset-n-active-state {
		pins = "gpio133";
		function = "gpio";
		drive-strength = <8>;
		bias-disable;
	};

	disp_reset_n_suspend: disp-reset-n-suspend-state {
		pins = "gpio133";
		function = "gpio";
		drive-strength = <2>;
		bias-pull-down;
	};

	mdp_vsync_active: mdp-vsync-active-state {
		pins = "gpio86";
		function = "mdp_vsync";
		drive-strength = <2>;
		bias-pull-down;
	};

	mdp_vsync_suspend: mdp-vsync-suspend-state {
		pins = "gpio86";
		function = "mdp_vsync";
		drive-strength = <2>;
		bias-pull-down;
	};

	wlan_en: wlan-en-state {
		pins = "gpio16";
		function = "gpio";
		drive-strength = <8>;
		bias-pull-down;
	};

	ts_int_active: ts-int-active-state {
		pins = "gpio162";
		function = "gpio";
		drive-strength = <8>;
		bias-disable;
		input-enable;
	};

	ts_reset_active: ts-reset-active-state {
		pins = "gpio161";
		function = "gpio";
		drive-strength = <8>;
		bias-disable;
		output-high;
	};
};

&uart14 {
	status = "okay";

	bluetooth {
		compatible = "qcom,wcn7850-bt";

		vddrfacmn-supply = <&vreg_pmu_rfa_cmn>;
		vddaon-supply = <&vreg_pmu_aon_0p59>;
		vddwlcx-supply = <&vreg_pmu_wlcx_0p8>;
		vddwlmx-supply = <&vreg_pmu_wlmx_0p85>;
		vddrfa0p8-supply = <&vreg_pmu_rfa_0p8>;
		vddrfa1p2-supply = <&vreg_pmu_rfa_1p2>;
		vddrfa1p8-supply = <&vreg_pmu_rfa_1p8>;

		max-speed = <3200000>;
	};
};

&ufs_mem_hc {
	reset-gpios = <&tlmm 210 GPIO_ACTIVE_LOW>;

	vcc-supply = <&vreg_l17b_2p5>;
	vcc-max-microamp = <1300000>;
	vccq-supply = <&vreg_l1c_1p2>;
	vccq-max-microamp = <1200000>;

	status = "okay";
};

&ufs_mem_phy {
	compatible = "qcom,sm8550-qmp-ufs-phy";
	vdda-phy-supply = <&vreg_l1d_0p88>;
	vdda-pll-supply = <&vreg_l3i_1p2>;

	status = "okay";
};

&usb_1 {
	status = "okay";
	dr_mode = "otg";
	usb-role-switch;
};

&usb_1_dwc3_hs {
	remote-endpoint = <&pmic_glink_hs_in>;
};

&usb_1_hsphy {
	vdd-supply = <&vreg_l1i_0p88>;
	vdda12-supply = <&vreg_l3i_1p2>;

	phys = <&pm8550b_eusb2_repeater>;

	status = "okay";
};

&usb_dp_qmpphy {
	vdda-phy-supply = <&vreg_l3i_1p2>;
	vdda-pll-supply = <&vreg_l3g_0p91>;

	status = "okay";
};

&usb_dp_qmpphy_out {
	remote-endpoint = <&pmic_glink_ss_in>;
};

&xo_board {
	clock-frequency = <76800000>;
};

&i2c3 {
		status = "okay";

		wcd_usbss: typec-mux@e {
		compatible = "qcom,wcd9395-usbss", "qcom,wcd9390-usbss";
		reg = <0xe>;

		vdd-supply = <&vreg_l15b_1p8>;
		reset-gpios = <&tlmm 152 GPIO_ACTIVE_HIGH>;

		mode-switch;
		orientation-switch;

		ports {
			#address-cells = <1>;
			#size-cells = <0>;

			port@0 {
				reg = <0>;

				wcd_usbss_sbu_mux: endpoint {
					remote-endpoint = <&pmic_glink_sbu>;
				};
			};
		};
		};
};

&qup_i2c3_data_clk {

	bias-pull-up = <2200>;
};
